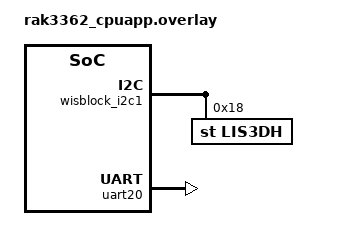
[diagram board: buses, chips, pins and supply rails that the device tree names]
/ {
	chosen {
		zephyr,console = &uart20;
	};
};

&wisblock_i2c1 {
	status = "okay";
	lis3dh: lis3dh@18 {
		compatible = "st,lis3dh", "st,lis2dh";
		reg = <0x18>;
	};
};

&uart20 {
	status = "okay";
};
